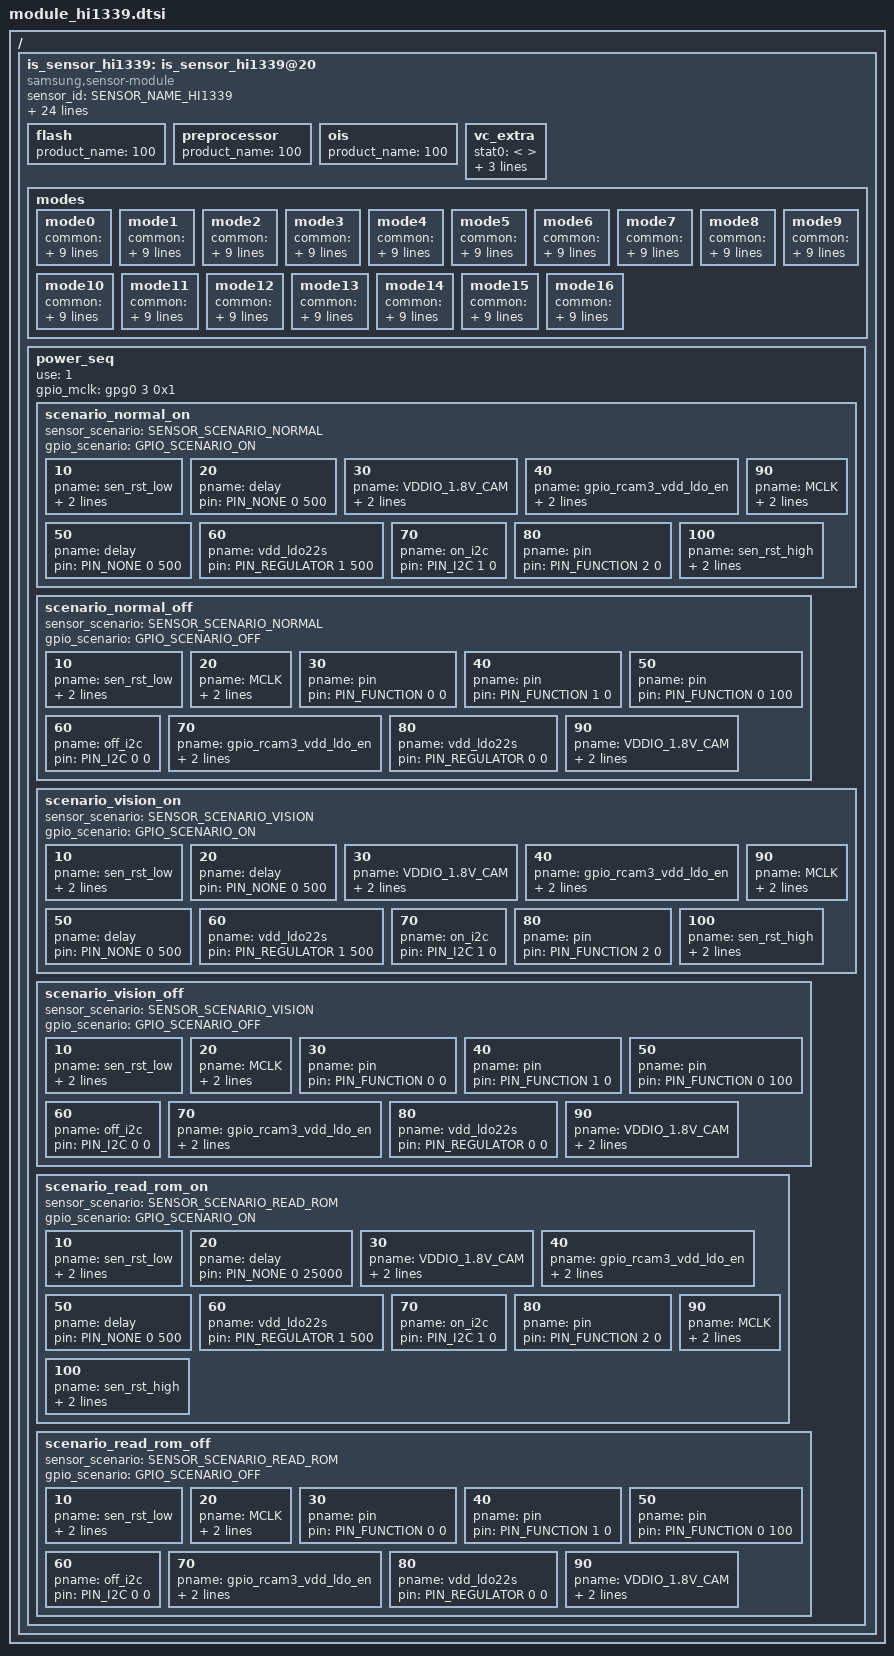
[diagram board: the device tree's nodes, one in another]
/*
 * SAMSUNG EXYNOSxxxx board camera device tree source
 *
 * Copyright (c) 2021 Samsung Electronics Co., Ltd.
 *		http://www.samsung.com
 *
 * This program is free software; you can redistribute it and/or modify
 * it under the terms of the GNU General Public License version 2 as
 * published by the Free Software Foundation.
 */

#include <dt-bindings/camera/exynos_is_dt.h>

/ {
	fragment@camera {
		target-path = "/";
		__overlay__ {
			is_sensor_hi1339: is_sensor_hi1339@20 {
				compatible = "samsung,sensor-module";

				/* common */
				sensor_id = <SENSOR_NAME_HI1339>;
				active_width = <4208>;
				active_height = <3120>;
				margin_left = <0>;
				margin_right = <0>;
				margin_top = <0>;
				margin_bottom = <0>;
				max_framerate = <120>;
				bitwidth = <10>;
				use_retention_mode = <SENSOR_RETENTION_UNSUPPORTED>;
				sensor_maker = "HYNIX";
				sensor_name = "HI1339";
				setfile_name = "setfile_hi1339.bin";

				status = "okay";

				/* board */
				pinctrl-names = "pin0", "pin1", "pin2", "release";
				pinctrl-0 = <>;
				pinctrl-1 = <&sensor_mclk1_out>;
				pinctrl-2 = <&sensor_mclk1_fn>;
				pinctrl-3 = <>;

				position = <1>;	/* Rear:0. Front:1. Rear_sub:2. Secure:3. */
				id = <1>; /* is_sensor id */
				mclk_ch = <1>;
				sensor_i2c_ch = <1>; /* SENSOR_CONTROL_I2C4 */

				/* vendor */
				rom_type = <3>; /* ROM_TYPE_OTPROM */
				rom_id = <1>;
				rom_cal_index = <0>;

				flash {
						product_name = <100>; /* NOTHING */
				};

				preprocessor {
						product_name = <100>; /* NOTHING */
				};

				ois {
						product_name = <100>; /* NOTHING */
				};

				vc_extra {
					/* ex) statX = <stat_type, sensor_mode, max_width, max_height, max_element> */
					stat0 = </* not available */>;	/* VC_BUF_DATA_TYPE_SENSOR_STAT1 */
					stat1 = </* not available */>;	/* VC_BUF_DATA_TYPE_GENERAL_STAT1 */
					stat2 = </* not available */>;	/* VC_BUF_DATA_TYPE_SENSOR_STAT2 */
					stat3 = </* not available */>;	/* VC_BUF_DATA_TYPE_GENERAL_STAT2 */
				};

				/*
				 * [Mode Information]
				 *
				 *  - Global setting
				 *
				 *
				 *
				 */

				/* sensor modes */
				modes {
						/* common = <width, height, fps, settle, mode, lane, speed, interleave, lrte, pd_mode> */
						/* vcX = <map, hwformat, width, height, hwformat, type, width, height> */
					/* Crop(4128x3096) 4:3 */
					mode0 {
						common = <4128 3096 30 0 0 CSI_DATA_LANES_4 1118 CSI_MODE_VC_ONLY LRTE_DISABLE PD_NONE EX_NONE>;
						vc0 = </* in */ 0 HW_FORMAT_RAW10 4128 3096	/* out */ HW_FORMAT_RAW10 VC_NOTHING 4128 3096>;
						vc1 = </* in */ 1 HW_FORMAT_UNKNOWN 0 0		/* out */ HW_FORMAT_UNKNOWN VC_NOTHING 0 0>;
						vc2 = </* in */ 2 HW_FORMAT_UNKNOWN 0 0		/* out */ HW_FORMAT_UNKNOWN VC_NOTHING 0 0>;
						vc3 = </* in */ 3 HW_FORMAT_UNKNOWN 0 0		/* out */ HW_FORMAT_UNKNOWN VC_NOTHING 0 0>;
					};

					/* Crop(4128x2324) */
					mode1 {
						common = <4128 2324 30 0 1 CSI_DATA_LANES_4 1118 CSI_MODE_VC_ONLY LRTE_DISABLE PD_NONE EX_NONE>;
						vc0 = </* in */ 0 HW_FORMAT_RAW10 4128 2324	/* out */ HW_FORMAT_RAW10 VC_NOTHING 4128 2324>;
						vc1 = </* in */ 1 HW_FORMAT_UNKNOWN 0 0		/* out */ HW_FORMAT_UNKNOWN VC_NOTHING 0 0>;
						vc2 = </* in */ 2 HW_FORMAT_UNKNOWN 0 0		/* out */ HW_FORMAT_UNKNOWN VC_NOTHING 0 0>;
						vc3 = </* in */ 3 HW_FORMAT_UNKNOWN 0 0		/* out */ HW_FORMAT_UNKNOWN VC_NOTHING 0 0>;
					};

					/* Crop(3712x2556) */
					mode2 {
						common = <3712 2556 30 0 2 CSI_DATA_LANES_4 1118 CSI_MODE_VC_ONLY LRTE_DISABLE PD_NONE EX_NONE>;
						vc0 = </* in */ 0 HW_FORMAT_RAW10 3712 2556	/* out */ HW_FORMAT_RAW10 VC_NOTHING 3712 2556>;
						vc1 = </* in */ 1 HW_FORMAT_UNKNOWN 0 0		/* out */ HW_FORMAT_UNKNOWN VC_NOTHING 0 0>;
						vc2 = </* in */ 2 HW_FORMAT_UNKNOWN 0 0		/* out */ HW_FORMAT_UNKNOWN VC_NOTHING 0 0>;
						vc3 = </* in */ 3 HW_FORMAT_UNKNOWN 0 0		/* out */ HW_FORMAT_UNKNOWN VC_NOTHING 0 0>;
					};

					/* Crop(3408x2556) */
					mode3 {
						common = <3408 2556 30 0 3 CSI_DATA_LANES_4 1118 CSI_MODE_VC_ONLY LRTE_DISABLE PD_NONE EX_NONE>;
						vc0 = </* in */ 0 HW_FORMAT_RAW10 3408 2556	/* out */ HW_FORMAT_RAW10 VC_NOTHING 3408 2556>;
						vc1 = </* in */ 1 HW_FORMAT_UNKNOWN 0 0		/* out */ HW_FORMAT_UNKNOWN VC_NOTHING 0 0>;
						vc2 = </* in */ 2 HW_FORMAT_UNKNOWN 0 0		/* out */ HW_FORMAT_UNKNOWN VC_NOTHING 0 0>;
						vc3 = </* in */ 3 HW_FORMAT_UNKNOWN 0 0		/* out */ HW_FORMAT_UNKNOWN VC_NOTHING 0 0>;
					};

					/* BIN4(1024x768) */
					mode4 {
						common = <1024 768 120 0 4 CSI_DATA_LANES_4 280 CSI_MODE_VC_ONLY LRTE_DISABLE PD_NONE EX_NONE>;
						vc0 = </* in */ 0 HW_FORMAT_RAW10 1024 768	/* out */ HW_FORMAT_RAW10 VC_NOTHING 1024 768>;
						vc1 = </* in */ 1 HW_FORMAT_UNKNOWN 0 0		/* out */ HW_FORMAT_UNKNOWN VC_NOTHING 0 0>;
						vc2 = </* in */ 2 HW_FORMAT_UNKNOWN 0 0		/* out */ HW_FORMAT_UNKNOWN VC_NOTHING 0 0>;
						vc3 = </* in */ 3 HW_FORMAT_UNKNOWN 0 0		/* out */ HW_FORMAT_UNKNOWN VC_NOTHING 0 0>;
					};

					/* BIN2(2064x1548) */
					mode5 {
						common = <2064 1548 30 0 5 CSI_DATA_LANES_4 559 CSI_MODE_VC_ONLY LRTE_DISABLE PD_NONE EX_NONE>;
						vc0 = </* in */ 0 HW_FORMAT_RAW10 2064 1548	/* out */ HW_FORMAT_RAW10 VC_NOTHING 2064 1548>;
						vc1 = </* in */ 1 HW_FORMAT_UNKNOWN 0 0		/* out */ HW_FORMAT_UNKNOWN VC_NOTHING 0 0>;
						vc2 = </* in */ 2 HW_FORMAT_UNKNOWN 0 0		/* out */ HW_FORMAT_UNKNOWN VC_NOTHING 0 0>;
						vc3 = </* in */ 3 HW_FORMAT_UNKNOWN 0 0		/* out */ HW_FORMAT_UNKNOWN VC_NOTHING 0 0>;
					};

					/* BIN2(2064x1160) */
					mode6 {
						common = <2064 1160 30 0 6 CSI_DATA_LANES_4 559 CSI_MODE_VC_ONLY LRTE_DISABLE PD_NONE EX_NONE>;
						vc0 = </* in */ 0 HW_FORMAT_RAW10 2064 1160	/* out */ HW_FORMAT_RAW10 VC_NOTHING 2064 1160>;
						vc1 = </* in */ 1 HW_FORMAT_UNKNOWN 0 0		/* out */ HW_FORMAT_UNKNOWN VC_NOTHING 0 0>;
						vc2 = </* in */ 2 HW_FORMAT_UNKNOWN 0 0		/* out */ HW_FORMAT_UNKNOWN VC_NOTHING 0 0>;
						vc3 = </* in */ 3 HW_FORMAT_UNKNOWN 0 0		/* out */ HW_FORMAT_UNKNOWN VC_NOTHING 0 0>;
					};

					/* BIN2(1696x1272) */
					mode7 {
						common = <1696 1272 30 0 7 CSI_DATA_LANES_4 559 CSI_MODE_VC_ONLY LRTE_DISABLE PD_NONE EX_NONE>;
						vc0 = </* in */ 0 HW_FORMAT_RAW10 1696 1272	/* out */ HW_FORMAT_RAW10 VC_NOTHING 1696 1272>;
						vc1 = </* in */ 1 HW_FORMAT_UNKNOWN 0 0		/* out */ HW_FORMAT_UNKNOWN VC_NOTHING 0 0>;
						vc2 = </* in */ 2 HW_FORMAT_UNKNOWN 0 0		/* out */ HW_FORMAT_UNKNOWN VC_NOTHING 0 0>;
						vc3 = </* in */ 3 HW_FORMAT_UNKNOWN 0 0		/* out */ HW_FORMAT_UNKNOWN VC_NOTHING 0 0>;
					};

					/* BIN2(1856x1044) */
					mode8 {
						common = <1856 1044 30 0 8 CSI_DATA_LANES_4 559 CSI_MODE_VC_ONLY LRTE_DISABLE PD_NONE EX_NONE>;
						vc0 = </* in */ 0 HW_FORMAT_RAW10 1856 1044	/* out */ HW_FORMAT_RAW10 VC_NOTHING 1856 1044>;
						vc1 = </* in */ 1 HW_FORMAT_UNKNOWN 0 0		/* out */ HW_FORMAT_UNKNOWN VC_NOTHING 0 0>;
						vc2 = </* in */ 2 HW_FORMAT_UNKNOWN 0 0		/* out */ HW_FORMAT_UNKNOWN VC_NOTHING 0 0>;
						vc3 = </* in */ 3 HW_FORMAT_UNKNOWN 0 0		/* out */ HW_FORMAT_UNKNOWN VC_NOTHING 0 0>;
					};

					/* BIN2(2064x1548) */
					mode9 {
						common = <2064 1548 15 0 9 CSI_DATA_LANES_4 559 CSI_MODE_VC_ONLY LRTE_DISABLE PD_NONE EX_NONE>;
						vc0 = </* in */ 0 HW_FORMAT_RAW10 2064 1548	/* out */ HW_FORMAT_RAW10 VC_NOTHING 2064 1548>;
						vc1 = </* in */ 1 HW_FORMAT_UNKNOWN 0 0		/* out */ HW_FORMAT_UNKNOWN VC_NOTHING 0 0>;
						vc2 = </* in */ 2 HW_FORMAT_UNKNOWN 0 0		/* out */ HW_FORMAT_UNKNOWN VC_NOTHING 0 0>;
						vc3 = </* in */ 3 HW_FORMAT_UNKNOWN 0 0		/* out */ HW_FORMAT_UNKNOWN VC_NOTHING 0 0>;
					};

					/* BIN2(2064x1160) */
					mode10 {
						common = <2064 1160 15 0 10 CSI_DATA_LANES_4 559 CSI_MODE_VC_ONLY LRTE_DISABLE PD_NONE EX_NONE>;
						vc0 = </* in */ 0 HW_FORMAT_RAW10 2064 1160	/* out */ HW_FORMAT_RAW10 VC_NOTHING 2064 1160>;
						vc1 = </* in */ 1 HW_FORMAT_UNKNOWN 0 0		/* out */ HW_FORMAT_UNKNOWN VC_NOTHING 0 0>;
						vc2 = </* in */ 2 HW_FORMAT_UNKNOWN 0 0		/* out */ HW_FORMAT_UNKNOWN VC_NOTHING 0 0>;
						vc3 = </* in */ 3 HW_FORMAT_UNKNOWN 0 0		/* out */ HW_FORMAT_UNKNOWN VC_NOTHING 0 0>;
					};

					/* BIN2(1696x1272) */
					mode11 {
						common = <1696 1272 15 0 11 CSI_DATA_LANES_4 559 CSI_MODE_VC_ONLY LRTE_DISABLE PD_NONE EX_NONE>;
						vc0 = </* in */ 0 HW_FORMAT_RAW10 1696 1272	/* out */ HW_FORMAT_RAW10 VC_NOTHING 1696 1272>;
						vc1 = </* in */ 1 HW_FORMAT_UNKNOWN 0 0		/* out */ HW_FORMAT_UNKNOWN VC_NOTHING 0 0>;
						vc2 = </* in */ 2 HW_FORMAT_UNKNOWN 0 0		/* out */ HW_FORMAT_UNKNOWN VC_NOTHING 0 0>;
						vc3 = </* in */ 3 HW_FORMAT_UNKNOWN 0 0		/* out */ HW_FORMAT_UNKNOWN VC_NOTHING 0 0>;
					};

					/* BIN2(1856x1044) */
					mode12 {
						common = <1856 1044 15 0 12 CSI_DATA_LANES_4 559 CSI_MODE_VC_ONLY LRTE_DISABLE PD_NONE EX_NONE>;
						vc0 = </* in */ 0 HW_FORMAT_RAW10 1856 1044	/* out */ HW_FORMAT_RAW10 VC_NOTHING 1856 1044>;
						vc1 = </* in */ 1 HW_FORMAT_UNKNOWN 0 0		/* out */ HW_FORMAT_UNKNOWN VC_NOTHING 0 0>;
						vc2 = </* in */ 2 HW_FORMAT_UNKNOWN 0 0		/* out */ HW_FORMAT_UNKNOWN VC_NOTHING 0 0>;
						vc3 = </* in */ 3 HW_FORMAT_UNKNOWN 0 0		/* out */ HW_FORMAT_UNKNOWN VC_NOTHING 0 0>;
					};
					/* BIN2(2064x1548) */
					mode13 {
						common = <2064 1548 7 0 13 CSI_DATA_LANES_4 559 CSI_MODE_VC_ONLY LRTE_DISABLE PD_NONE EX_NONE>;
						vc0 = </* in */ 0 HW_FORMAT_RAW10 2064 1548	/* out */ HW_FORMAT_RAW10 VC_NOTHING 2064 1548>;
						vc1 = </* in */ 1 HW_FORMAT_UNKNOWN 0 0		/* out */ HW_FORMAT_UNKNOWN VC_NOTHING 0 0>;
						vc2 = </* in */ 2 HW_FORMAT_UNKNOWN 0 0		/* out */ HW_FORMAT_UNKNOWN VC_NOTHING 0 0>;
						vc3 = </* in */ 3 HW_FORMAT_UNKNOWN 0 0		/* out */ HW_FORMAT_UNKNOWN VC_NOTHING 0 0>;
					};

					/* BIN2(2064x1160) */
					mode14 {
						common = <2064 1160 7 0 14 CSI_DATA_LANES_4 559 CSI_MODE_VC_ONLY LRTE_DISABLE PD_NONE EX_NONE>;
						vc0 = </* in */ 0 HW_FORMAT_RAW10 2064 1160	/* out */ HW_FORMAT_RAW10 VC_NOTHING 2064 1160>;
						vc1 = </* in */ 1 HW_FORMAT_UNKNOWN 0 0		/* out */ HW_FORMAT_UNKNOWN VC_NOTHING 0 0>;
						vc2 = </* in */ 2 HW_FORMAT_UNKNOWN 0 0		/* out */ HW_FORMAT_UNKNOWN VC_NOTHING 0 0>;
						vc3 = </* in */ 3 HW_FORMAT_UNKNOWN 0 0		/* out */ HW_FORMAT_UNKNOWN VC_NOTHING 0 0>;
					};

					/* BIN2(1696x1272) */
					mode15 {
						common = <1696 1272 7 0 15 CSI_DATA_LANES_4 559 CSI_MODE_VC_ONLY LRTE_DISABLE PD_NONE EX_NONE>;
						vc0 = </* in */ 0 HW_FORMAT_RAW10 1696 1272	/* out */ HW_FORMAT_RAW10 VC_NOTHING 1696 1272>;
						vc1 = </* in */ 1 HW_FORMAT_UNKNOWN 0 0		/* out */ HW_FORMAT_UNKNOWN VC_NOTHING 0 0>;
						vc2 = </* in */ 2 HW_FORMAT_UNKNOWN 0 0		/* out */ HW_FORMAT_UNKNOWN VC_NOTHING 0 0>;
						vc3 = </* in */ 3 HW_FORMAT_UNKNOWN 0 0		/* out */ HW_FORMAT_UNKNOWN VC_NOTHING 0 0>;
					};

					/* BIN2(1856x1044) */
					mode16 {
						common = <1856 1044 7 0 16 CSI_DATA_LANES_4 559 CSI_MODE_VC_ONLY LRTE_DISABLE PD_NONE EX_NONE>;
						vc0 = </* in */ 0 HW_FORMAT_RAW10 1856 1044	/* out */ HW_FORMAT_RAW10 VC_NOTHING 1856 1044>;
						vc1 = </* in */ 1 HW_FORMAT_UNKNOWN 0 0		/* out */ HW_FORMAT_UNKNOWN VC_NOTHING 0 0>;
						vc2 = </* in */ 2 HW_FORMAT_UNKNOWN 0 0		/* out */ HW_FORMAT_UNKNOWN VC_NOTHING 0 0>;
						vc3 = </* in */ 3 HW_FORMAT_UNKNOWN 0 0		/* out */ HW_FORMAT_UNKNOWN VC_NOTHING 0 0>;
					};										
				};

				power_seq {
					use = <1>;
					gpio_mclk = <&gpg0 3 0x1>;

					scenario_normal_on {
						sensor_scenario = <SENSOR_SCENARIO_NORMAL>;
						gpio_scenario = <GPIO_SCENARIO_ON>;

						/* A start node number should be over the 10 for reserved number 0~9. */
						/* pname = "name"; pin = <act value delay voltage>; gpio = <gpx# # 0x1>; */
						10 { pname = "sen_rst_low"; pin = <PIN_OUTPUT 0 0>; gpio = <&gpm13 0 0x1>; };
						20 { pname = "delay"; pin = <PIN_NONE 0 500>; };
						30 { pname = "VDDIO_1.8V_CAM"; pin = <PIN_OUTPUT 1 0>; gpio = <&gpm10 0 0x1>; };
						40 { pname = "gpio_rcam3_vdd_ldo_en"; pin = <PIN_OUTPUT 1 0>; gpio = <&gpm9 0 0x1>; };
						50 { pname = "delay"; pin = <PIN_NONE 0 500>; };
						60 { pname = "vdd_ldo22s"; pin = <PIN_REGULATOR 1 500>; };
						70 { pname = "on_i2c"; pin = <PIN_I2C 1 0>; };
						80 { pname = "pin"; pin = <PIN_FUNCTION 2 0>; };
						90 { pname = "MCLK"; pin = <PIN_MCLK 1 500>; gpio = <&gpg0 3 0x1>; };
						100 { pname = "sen_rst_high"; pin = <PIN_OUTPUT 1 9000>; gpio = <&gpm13 0 0x1>; };
					};

					scenario_normal_off {
						sensor_scenario = <SENSOR_SCENARIO_NORMAL>;
						gpio_scenario = <GPIO_SCENARIO_OFF>;

						/* A start node number should be over the 10 for reserved number 0~9. */
						/* pname = "name"; pin = <act value delay voltage>; gpio = <gpx# # 0x1>; */
						10 { pname = "sen_rst_low"; pin = <PIN_OUTPUT 0 0>; gpio = <&gpm13 0 0x1>; };
						20 { pname = "MCLK"; pin = <PIN_MCLK 0 500>; gpio = <&gpg0 3 0x1>; };
						30 { pname = "pin"; pin = <PIN_FUNCTION 0 0>; };
						40 { pname = "pin"; pin = <PIN_FUNCTION 1 0>; };
						50 { pname = "pin"; pin = <PIN_FUNCTION 0 100>; };
						60 { pname = "off_i2c"; pin = <PIN_I2C 0 0>; };
						70 { pname = "gpio_rcam3_vdd_ldo_en"; pin = <PIN_OUTPUT 0 0>; gpio = <&gpm9 0 0x1>; };
						80 { pname = "vdd_ldo22s"; pin = <PIN_REGULATOR 0 0>; };
						90 { pname = "VDDIO_1.8V_CAM"; pin = <PIN_OUTPUT 0 0>; gpio = <&gpm10 0 0x1>; };
					};

					scenario_vision_on {
						sensor_scenario = <SENSOR_SCENARIO_VISION>;
						gpio_scenario = <GPIO_SCENARIO_ON>;

						/* A start node number should be over the 10 for reserved number 0~9. */
						/* pname = "name"; pin = <act value delay voltage>; gpio = <gpx# # 0x1>; */
						10 { pname = "sen_rst_low"; pin = <PIN_OUTPUT 0 0>; gpio = <&gpm13 0 0x1>; };
						20 { pname = "delay"; pin = <PIN_NONE 0 500>; };
						30 { pname = "VDDIO_1.8V_CAM"; pin = <PIN_OUTPUT 1 0>; gpio = <&gpm10 0 0x1>; };
						40 { pname = "gpio_rcam3_vdd_ldo_en"; pin = <PIN_OUTPUT 1 0>; gpio = <&gpm9 0 0x1>; };
						50 { pname = "delay"; pin = <PIN_NONE 0 500>; };
						60 { pname = "vdd_ldo22s"; pin = <PIN_REGULATOR 1 500>; };
						70 { pname = "on_i2c"; pin = <PIN_I2C 1 0>; };
						80 { pname = "pin"; pin = <PIN_FUNCTION 2 0>; };
						90 { pname = "MCLK"; pin = <PIN_MCLK 1 500>; gpio = <&gpg0 3 0x1>; };
						100 { pname = "sen_rst_high"; pin = <PIN_OUTPUT 1 9000>; gpio = <&gpm13 0 0x1>; };
					};

					scenario_vision_off {
						sensor_scenario = <SENSOR_SCENARIO_VISION>;
						gpio_scenario = <GPIO_SCENARIO_OFF>;

						/* A start node number should be over the 10 for reserved number 0~9. */
						/* pname = "name"; pin = <act value delay voltage>; gpio = <gpx# # 0x1>; */
						10 { pname = "sen_rst_low"; pin = <PIN_OUTPUT 0 0>; gpio = <&gpm13 0 0x1>; };
						20 { pname = "MCLK"; pin = <PIN_MCLK 0 500>; gpio = <&gpg0 3 0x1>; };
						30 { pname = "pin"; pin = <PIN_FUNCTION 0 0>; };
						40 { pname = "pin"; pin = <PIN_FUNCTION 1 0>; };
						50 { pname = "pin"; pin = <PIN_FUNCTION 0 100>; };
						60 { pname = "off_i2c"; pin = <PIN_I2C 0 0>; };
						70 { pname = "gpio_rcam3_vdd_ldo_en"; pin = <PIN_OUTPUT 0 0>; gpio = <&gpm9 0 0x1>; };
						80 { pname = "vdd_ldo22s"; pin = <PIN_REGULATOR 0 0>; };
						90 { pname = "VDDIO_1.8V_CAM"; pin = <PIN_OUTPUT 0 0>; gpio = <&gpm10 0 0x1>; };
					};

					scenario_read_rom_on {
						sensor_scenario = <SENSOR_SCENARIO_READ_ROM>;
						gpio_scenario = <GPIO_SCENARIO_ON>;
						/* pname = "name"; pin = <act value delay voltage>; gpio = <gpx# # 0x1>; */
						10 { pname = "sen_rst_low"; pin = <PIN_OUTPUT 0 0>; gpio = <&gpm13 0 0x1>; };
						20 { pname = "delay"; pin = <PIN_NONE 0 25000>; };
						30 { pname = "VDDIO_1.8V_CAM"; pin = <PIN_OUTPUT 1 0>; gpio = <&gpm10 0 0x1>; };
						40 { pname = "gpio_rcam3_vdd_ldo_en"; pin = <PIN_OUTPUT 1 0>; gpio = <&gpm9 0 0x1>; };
						50 { pname = "delay"; pin = <PIN_NONE 0 500>; };
						60 { pname = "vdd_ldo22s"; pin = <PIN_REGULATOR 1 500>; };
						70 { pname = "on_i2c"; pin = <PIN_I2C 1 0>; };
						80 { pname = "pin"; pin = <PIN_FUNCTION 2 0>; };
						90 { pname = "MCLK"; pin = <PIN_MCLK 1 500>; gpio = <&gpg0 3 0x1>; };
						100 { pname = "sen_rst_high"; pin = <PIN_OUTPUT 1 9000>; gpio = <&gpm13 0 0x1>; };
					};

					scenario_read_rom_off {
						sensor_scenario = <SENSOR_SCENARIO_READ_ROM>;
						gpio_scenario = <GPIO_SCENARIO_OFF>;
						/* pname = "name"; pin = <act value delay voltage>; gpio = <gpx# # 0x1>; */
						10 { pname = "sen_rst_low"; pin = <PIN_OUTPUT 0 0>; gpio = <&gpm13 0 0x1>; };
						20 { pname = "MCLK"; pin = <PIN_MCLK 0 500>; gpio = <&gpg0 3 0x1>; };
						30 { pname = "pin"; pin = <PIN_FUNCTION 0 0>; };
						40 { pname = "pin"; pin = <PIN_FUNCTION 1 0>; };
						50 { pname = "pin"; pin = <PIN_FUNCTION 0 100>; };
						60 { pname = "off_i2c"; pin = <PIN_I2C 0 0>; };
						70 { pname = "gpio_rcam3_vdd_ldo_en"; pin = <PIN_OUTPUT 0 0>; gpio = <&gpm9 0 0x1>; };
						80 { pname = "vdd_ldo22s"; pin = <PIN_REGULATOR 0 0>; };
						90 { pname = "VDDIO_1.8V_CAM"; pin = <PIN_OUTPUT 0 0>; gpio = <&gpm10 0 0x1>; };
					};
				};
			};
		}; /* end of __overlay__ */
	}; /* end of fragment */
}; /* end of root */
